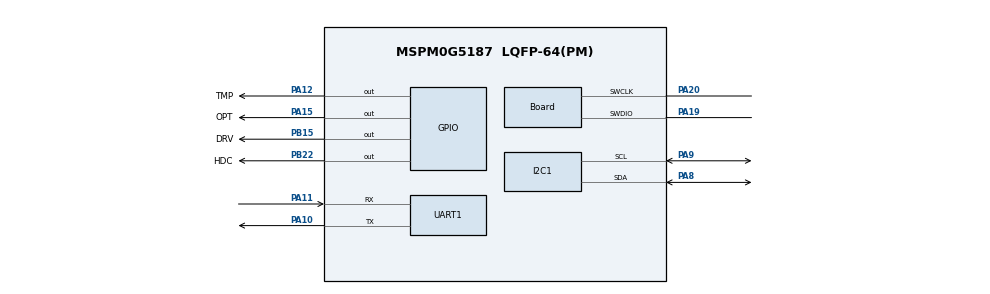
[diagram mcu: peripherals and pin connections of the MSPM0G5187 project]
//@cliArgs --device "MSPM0G518X" --package "LQFP-64(PM)" --part "Default"
//@v2CliArgs --device "MSPM0G5187" --package "LQFP-64(PM)"
// @cliArgs --board /ti/boards/LP_MSPM0G5187 --rtos nortos
// BP-BASSENSORSMKII on the LP-MSPM0G5187. Generated by boards/gen_syscfg.py; edit the table there.
// I2C controller 100 kHz on BoosterPack pins 9 (SCL) and 10 (SDA); four power-switch pins; DRV5055 output on ADC; backchannel UART 115200.
const Board  = scripting.addModule("/ti/driverlib/Board", {}, false);
const GPIO   = scripting.addModule("/ti/driverlib/GPIO", {}, false);
const I2C    = scripting.addModule("/ti/driverlib/I2C", {}, false);
const SYSCTL = scripting.addModule("/ti/driverlib/SYSCTL");
const UART   = scripting.addModule("/ti/driverlib/UART", {}, false);

const ADC12  = scripting.addModule("/ti/driverlib/ADC12", {}, false);
const ADC121 = ADC12.addInstance();
const I2C1   = I2C.addInstance();
const UART1  = UART.addInstance();
const g_hdc = GPIO.addInstance();
g_hdc.$name = "HDC_PWR";
g_hdc.associatedPins[0].$name = "HDC";
g_hdc.associatedPins[0].pin.$assign = "PB22";
g_hdc.associatedPins[0].initialValue = "SET";
const g_drv = GPIO.addInstance();
g_drv.$name = "DRV_PWR";
g_drv.associatedPins[0].$name = "DRV";
g_drv.associatedPins[0].pin.$assign = "PB15";
g_drv.associatedPins[0].initialValue = "SET";
const g_opt = GPIO.addInstance();
g_opt.$name = "OPT_PWR";
g_opt.associatedPins[0].$name = "OPT";
g_opt.associatedPins[0].pin.$assign = "PA15";
const g_tmp = GPIO.addInstance();
g_tmp.$name = "TMP_PWR";
g_tmp.associatedPins[0].$name = "TMP";
g_tmp.associatedPins[0].pin.$assign = "PA12";

ADC121.$name                       = "ADC12_0";
ADC121.sampClkSrc                  = "DL_ADC12_CLOCK_ULPCLK";
ADC121.sampClkDiv                  = "DL_ADC12_CLOCK_DIVIDE_8";
ADC121.sampleTime0                 = "125 us";
ADC121.powerDownMode               = "DL_ADC12_POWER_DOWN_MODE_MANUAL";
ADC121.adcMem0chansel              = "DL_ADC12_INPUT_CHAN_2";
ADC121.peripheral.adcPin2.$assign  = "PA25";

Board.peripheral.$assign          = "DEBUGSS";
Board.peripheral.swclkPin.$assign = "PA20";
Board.peripheral.swdioPin.$assign = "PA19";

I2C1.$name                     = "I2C";
I2C1.basicEnableController     = true;
I2C1.basicControllerBusSpeed   = 100000;
I2C1.peripheral.sdaPin.$assign = "PA8";
I2C1.peripheral.sclPin.$assign = "PA9";

UART1.$name                    = "UART_0";
UART1.enableFIFO               = true;
UART1.targetBaudRate           = 115200;
UART1.peripheral.$assign       = "UC0";
UART1.peripheral.rxPin.$assign = "PA11";
UART1.peripheral.txPin.$assign = "PA10";

SYSCTL.forceDefaultClkConfig = true;
SYSCTL.clockTreeEn           = true;

const ProjectConfig              = scripting.addModule("/ti/project_config/ProjectConfig", {}, false);
ProjectConfig.migrationCondition = true;
